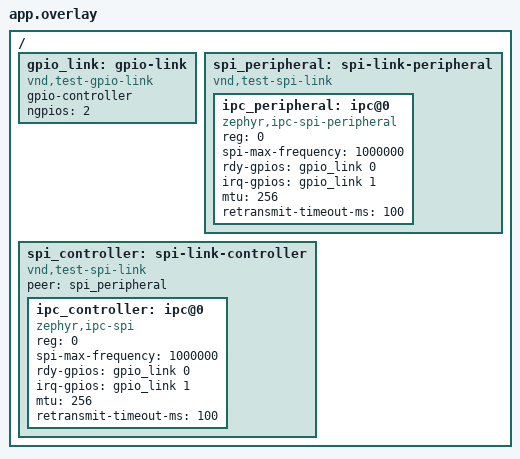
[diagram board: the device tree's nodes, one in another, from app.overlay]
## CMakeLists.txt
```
# SPDX-FileCopyrightText: Copyright (c) 2026 Basalte bv
# SPDX-License-Identifier: Apache-2.0

cmake_minimum_required(VERSION 3.28.0)
find_package(Zephyr REQUIRED HINTS $ENV{ZEPHYR_BASE})
project(ipc_link_spi)

target_sources(app PRIVATE src/main.c src/gpio_link.c src/spi_link.c)
```

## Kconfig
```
# SPDX-FileCopyrightText: Copyright (c) 2026 Basalte bv
# SPDX-License-Identifier: Apache-2.0

config TEST_IPC_LINK_SPI_MISMATCH
	bool "Test a peripheral with another frame size"
	help
	  Build the test of a controller facing a peripheral that runs
	  another frame size, with the mismatch overlay, instead of the
	  tests of a matching pair.

source "Kconfig.zephyr"
```

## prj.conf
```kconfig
CONFIG_ZTEST=y
CONFIG_IPC_SERVICE=y
CONFIG_IPC_SERVICE_LINK_STATS=y
CONFIG_GPIO=y
CONFIG_SPI=y
CONFIG_SPI_ASYNC=y
CONFIG_SPI_PERIPHERAL=y
```

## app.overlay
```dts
/*
 * SPDX-FileCopyrightText: Copyright (c) 2026 Basalte bv
 * SPDX-License-Identifier: Apache-2.0
 */

#include <zephyr/dt-bindings/gpio/gpio.h>

/ {
	gpio_link: gpio-link {
		compatible = "vnd,test-gpio-link";
		gpio-controller;
		#gpio-cells = <2>;
		ngpios = <2>;
	};

	spi_peripheral: spi-link-peripheral {
		compatible = "vnd,test-spi-link";
		#address-cells = <1>;
		#size-cells = <0>;

		ipc_peripheral: ipc@0 {
			compatible = "zephyr,ipc-spi-peripheral";
			reg = <0>;
			spi-max-frequency = <1000000>;
			rdy-gpios = <&gpio_link 0 GPIO_ACTIVE_HIGH>;
			irq-gpios = <&gpio_link 1 GPIO_ACTIVE_HIGH>;
			mtu = <256>;
			retransmit-timeout-ms = <100>;
		};
	};

	spi_controller: spi-link-controller {
		compatible = "vnd,test-spi-link";
		#address-cells = <1>;
		#size-cells = <0>;
		peer = <&spi_peripheral>;

		ipc_controller: ipc@0 {
			compatible = "zephyr,ipc-spi";
			reg = <0>;
			spi-max-frequency = <1000000>;
			rdy-gpios = <&gpio_link 0 GPIO_ACTIVE_HIGH>;
			irq-gpios = <&gpio_link 1 GPIO_ACTIVE_HIGH>;
			mtu = <256>;
			retransmit-timeout-ms = <100>;
		};
	};
};
```

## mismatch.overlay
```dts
/*
 * SPDX-FileCopyrightText: Copyright (c) 2026 Basalte bv
 * SPDX-License-Identifier: Apache-2.0
 */

/* The peripheral runs another frame size than the controller, and both probe slowly */
&ipc_peripheral {
	mtu = <128>;
	retransmit-timeout-ms = <1000>;
};

&ipc_controller {
	retransmit-timeout-ms = <1000>;
};
```

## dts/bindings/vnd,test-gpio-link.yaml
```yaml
# SPDX-FileCopyrightText: Copyright (c) 2026 Basalte bv
# SPDX-License-Identifier: Apache-2.0

description: |
  Test GPIO port whose pins are wires between two drivers in one image: a level written by one
  is read by the other, and fires its edge interrupts.

compatible: "vnd,test-gpio-link"

include: [gpio-controller.yaml, base.yaml]

properties:
  "#gpio-cells":
    const: 2

gpio-cells:
  - pin
  - flags
```

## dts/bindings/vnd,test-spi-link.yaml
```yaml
# SPDX-FileCopyrightText: Copyright (c) 2026 Basalte bv
# SPDX-License-Identifier: Apache-2.0

description: |
  Test SPI bus of a pair: a transfer on the controller bus runs against the transfer armed on
  its peer, the peripheral bus.

compatible: "vnd,test-spi-link"

include: spi-controller.yaml

properties:
  peer:
    type: phandle
    description: The peripheral bus, only set on the controller bus.
```

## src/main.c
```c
/*
 * SPDX-FileCopyrightText: Copyright (c) 2026 Basalte bv
 * SPDX-License-Identifier: Apache-2.0
 */

/*
 * A controller and a peripheral IPC link instance in one image, over a test SPI bus pair and a
 * test GPIO port, so both transfer threads, RDY and IRQ run as on two MCUs.
 */

#include <errno.h>
#include <string.h>

#include <zephyr/device.h>
#include <zephyr/drivers/gpio.h>
#include <zephyr/ipc/ipc_link.h>
#include <zephyr/ipc/ipc_service.h>
#include <zephyr/kernel.h>
#include <zephyr/sys/byteorder.h>
#include <zephyr/ztest.h>

#define BIND_TIMEOUT 1000
#define STREAM_COUNT 300
#define RETX_MS      DT_PROP(DT_NODELABEL(ipc_controller), retransmit_timeout_ms)
#define MAX_RETX     CONFIG_IPC_SERVICE_BACKEND_LINK_MAX_RETRANSMITS
/* Long enough for the retransmissions to end a session */
#define GONE_MS      (2 * (MAX_RETX + 1) * RETX_MS)

#define RDY_PIN DT_GPIO_PIN(DT_NODELABEL(ipc_controller), rdy_gpios)

static const struct device *const dev_c = DEVICE_DT_GET(DT_NODELABEL(ipc_controller));
static const struct device *const dev_p = DEVICE_DT_GET(DT_NODELABEL(ipc_peripheral));

extern atomic_t spi_link_transfers;

struct test_ept {
	struct ipc_ept ept;
	struct ipc_ept_cfg cfg;
	struct k_sem bound;
	struct k_sem unbound;
	struct k_sem received;
	uint8_t last[256];
	size_t last_len;
	uint32_t count;
	bool echo;
	bool stream;
	uint32_t expected;
	int error;
	/* Keep the received buffers */
	bool hold;
	const void *held[CONFIG_IPC_SERVICE_BACKEND_LINK_RX_BUFFERS];
	size_t held_count;
};

static void test_bound(void *priv)
{
	struct test_ept *t = priv;

	k_sem_give(&t->bound);
}

static void test_unbound(void *priv)
{
	struct test_ept *t = priv;

	k_sem_give(&t->unbound);
}

static void test_received(const void *data, size_t len, void *priv)
{
	struct test_ept *t = priv;

	t->count++;

	if (t->stream) {
		if (len != sizeof(uint32_t) || sys_get_le32(data) != t->expected) {
			t->error = -EBADMSG;
		}
		t->expected++;
	}

	if (len <= sizeof(t->last)) {
		memcpy(t->last, data, len);
		t->last_len = len;
	}

	if (t->echo) {
		int ret = ipc_service_send(&t->ept, data, len);

		if (ret < 0) {
			t->error = ret;
		}
	}

	if (t->hold && t->held_count < ARRAY_SIZE(t->held)) {
		if (ipc_service_hold_rx_buffer(&t->ept, (void *)data) == 0) {
			t->held[t->held_count++] = data;
		}
	}

	k_sem_give(&t->received);
}

static void test_ept_init(struct test_ept *t, const char *name)
{
	memset(t, 0, sizeof(*t));
	t->cfg.name = name;
	t->cfg.priv = t;
	t->cfg.cb.bound = test_bound;
	t->cfg.cb.unbound = test_unbound;
	t->cfg.cb.received = test_received;
	k_sem_init(&t->bound, 0, 1);
	k_sem_init(&t->unbound, 0, 1);
	k_sem_init(&t->received, 0, K_SEM_MAX_LIMIT);
}

static struct test_ept ept_c;

static uint32_t stat_get(const struct device *dev, size_t offset)
{
	struct ipc_link_stats stats;

	zassert_ok(ipc_link_stats_get(dev, &stats));

	return *(uint32_t *)((uint8_t *)&stats + offset);
}

#define STAT(dev, name) stat_get(dev, offsetof(struct ipc_link_stats, name))

static void *suite_setup(void)
{
	zassert_ok(ipc_service_open_instance(dev_p));
	zassert_ok(ipc_service_open_instance(dev_c));

	return NULL;
}

#ifdef CONFIG_TEST_IPC_LINK_SPI_MISMATCH

ZTEST_SUITE(ipc_link_spi_mismatch, NULL, suite_setup, NULL, NULL, NULL);

/* The peripheral runs another frame size: each side probes it once per timeout, no more */
ZTEST(ipc_link_spi_mismatch, test_probed_slowly)
{
	atomic_val_t transfers;

	k_sleep(K_MSEC(3 * RETX_MS));

	transfers = atomic_get(&spi_link_transfers);
	zassert_true(transfers >= 2 && transfers <= 8, "%ld transactions in %d ms", (long)transfers,
		     3 * RETX_MS);
	zexpect_true(STAT(dev_c, peer_mismatches) > 0);

	test_ept_init(&ept_c, "echo");
	zassert_ok(ipc_service_register_endpoint(dev_c, &ept_c.ept, &ept_c.cfg));
	zassert_equal(k_sem_take(&ept_c.bound, K_MSEC(RETX_MS)), -EAGAIN);
}

#else

static const struct device *const gpio = DEVICE_DT_GET(DT_NODELABEL(gpio_link));
static struct test_ept ept_p;
static struct test_ept ept_c2;

void spi_link_pulse(const struct device *dev);
void spi_link_unplug(bool unplugged);

/* Sends, waiting for room up to a timeout: the backend itself never waits */
static int send_wait(struct ipc_ept *ept, const void *data, size_t len, uint32_t timeout_ms)
{
	int64_t end = k_uptime_get() + timeout_ms;
	int ret;

	while (true) {
		ret = ipc_service_send(ept, data, len);
		if (ret != -ENOMEM || k_uptime_get() >= end) {
			return ret;
		}

		k_sleep(K_MSEC(1));
	}
}

static void register_pair(void)
{
	zassert_ok(ipc_service_register_endpoint(dev_p, &ept_p.ept, &ept_p.cfg));
	zassert_ok(ipc_service_register_endpoint(dev_c, &ept_c.ept, &ept_c.cfg));
	zassert_ok(k_sem_take(&ept_c.bound, K_MSEC(BIND_TIMEOUT)));
	zassert_ok(k_sem_take(&ept_p.bound, K_MSEC(BIND_TIMEOUT)));
}

static void before(void *fixture)
{
	ARG_UNUSED(fixture);

	test_ept_init(&ept_c, "echo");
	test_ept_init(&ept_p, "echo");
	test_ept_init(&ept_c2, "other");
}

static void after(void *fixture)
{
	struct test_ept *epts[] = {&ept_c, &ept_p, &ept_c2};

	ARG_UNUSED(fixture);

	spi_link_unplug(false);

	for (size_t i = 0; i < ARRAY_SIZE(epts); i++) {
		while (epts[i]->held_count > 0) {
			(void)ipc_service_release_rx_buffer(
				&epts[i]->ept, (void *)epts[i]->held[--epts[i]->held_count]);
		}

		(void)ipc_service_deregister_endpoint(&epts[i]->ept);
	}
}

ZTEST_SUITE(ipc_link_spi, NULL, suite_setup, before, after, NULL);

static void echo(struct test_ept *from, struct test_ept *to)
{
	to->echo = true;

	register_pair();

	zassert_equal(ipc_service_send(&from->ept, "hello", 5), 5);
	zassert_ok(k_sem_take(&from->received, K_MSEC(1000)));
	zassert_equal(from->last_len, 5);
	zassert_mem_equal(from->last, "hello", 5);
	zassert_equal(to->error, 0);
}

ZTEST(ipc_link_spi, test_echo_from_controller)
{
	echo(&ept_c, &ept_p);
}

/* The peripheral starts: its IRQ line makes the controller clock */
ZTEST(ipc_link_spi, test_echo_from_peripheral)
{
	echo(&ept_p, &ept_c);
}

ZTEST(ipc_link_spi, test_bind_later)
{
	/* The controller registers first, and binds once the peripheral registers */
	zassert_ok(ipc_service_register_endpoint(dev_c, &ept_c.ept, &ept_c.cfg));
	zassert_equal(k_sem_take(&ept_c.bound, K_MSEC(2 * RETX_MS)), -EAGAIN);

	zassert_ok(ipc_service_register_endpoint(dev_p, &ept_p.ept, &ept_p.cfg));
	zassert_ok(k_sem_take(&ept_c.bound, K_MSEC(BIND_TIMEOUT)));
	zassert_ok(k_sem_take(&ept_p.bound, K_MSEC(BIND_TIMEOUT)));
}

ZTEST(ipc_link_spi, test_largest_message)
{
	uint8_t big[256];
	int max;

	ept_p.echo = true;
	register_pair();

	max = ipc_service_get_tx_buffer_size(&ept_c.ept);
	zassert_true(max > 0 && max < sizeof(big));
	for (int i = 0; i < max; i++) {
		big[i] = (uint8_t)i;
	}

	zassert_equal(ipc_service_send(&ept_c.ept, big, max + 1), -EMSGSIZE);
	/* A frame of its own: wait for the bind traffic to be acknowledged */
	zassert_equal(send_wait(&ept_c.ept, big, max, 1000), max);
	zassert_ok(k_sem_take(&ept_c.received, K_MSEC(1000)));
	zexpect_equal(ept_c.last_len, max);
	zexpect_mem_equal(ept_c.last, big, max);
}

ZTEST(ipc_link_spi, test_stream_both_ways)
{
	ept_c.stream = true;
	ept_p.stream = true;

	register_pair();

	for (uint32_t i = 0; i < STREAM_COUNT; i++) {
		uint8_t data[sizeof(uint32_t)];
		int ret;

		sys_put_le32(i, data);

		ret = send_wait(&ept_c.ept, data, sizeof(data), 1000);
		zassert_equal(ret, sizeof(data), "message %u to the peripheral: %d", i, ret);

		ret = send_wait(&ept_p.ept, data, sizeof(data), 1000);
		zassert_equal(ret, sizeof(data), "message %u to the controller: %d", i, ret);
	}

	for (uint32_t i = 0; i < STREAM_COUNT; i++) {
		zassert_ok(k_sem_take(&ept_c.received, K_MSEC(1000)), "message %u", i);
		zassert_ok(k_sem_take(&ept_p.received, K_MSEC(1000)), "message %u", i);
	}

	zexpect_equal(ept_c.count, STREAM_COUNT);
	zexpect_equal(ept_p.count, STREAM_COUNT);
	zexpect_equal(ept_c.error, 0);
	zexpect_equal(ept_p.error, 0);
}

ZTEST(ipc_link_spi, test_hold)
{
	size_t count = 0;
	uint8_t big[256];
	int max;

	ept_p.hold = true;
	register_pair();

	/* The peripheral keeps every buffer: the controller runs out of credits, then out of
	 * room. Once they are released, the peripheral has credits to give and nothing else: it
	 * must ask for the transaction that carries them with IRQ
	 */
	max = ipc_service_get_tx_buffer_size(&ept_c.ept);

	while (true) {
		int ret = send_wait(&ept_c.ept, big, max, 3 * RETX_MS);

		if (ret == -ENOMEM) {
			break;
		}

		zassert_equal(ret, max);
		count++;
		zassert_true(count < 100, "the controller never ran out of room");
	}

	zexpect_equal(ept_p.held_count, CONFIG_IPC_SERVICE_BACKEND_LINK_RX_BUFFERS - 1);

	while (ept_p.held_count > 0) {
		zassert_ok(ipc_service_release_rx_buffer(&ept_p.ept,
							 (void *)ept_p.held[--ept_p.held_count]));
	}
	ept_p.hold = false;

	for (size_t i = 0; i < count; i++) {
		zassert_ok(k_sem_take(&ept_p.received, K_MSEC(1000)), "message %zu", i);
	}
	zexpect_equal(ept_p.count, count);
}

ZTEST(ipc_link_spi, test_unbind)
{
	ept_p.echo = true;
	register_pair();

	zassert_ok(ipc_service_deregister_endpoint(&ept_p.ept));
	zassert_ok(k_sem_take(&ept_c.unbound, K_MSEC(1000)));
	zassert_equal(ipc_service_send(&ept_c.ept, "x", 1), -EBUSY);

	zassert_ok(ipc_service_register_endpoint(dev_p, &ept_p.ept, &ept_p.cfg));
	zassert_ok(k_sem_take(&ept_c.bound, K_MSEC(BIND_TIMEOUT)));
	zassert_ok(k_sem_take(&ept_p.bound, K_MSEC(BIND_TIMEOUT)));

	zassert_equal(ipc_service_send(&ept_c.ept, "again", 5), 5);
	zassert_ok(k_sem_take(&ept_c.received, K_MSEC(1000)));
	zexpect_mem_equal(ept_c.last, "again", 5);
}

/* Waits until the controller clocks nothing for a while and the peripheral is armed */
static void wait_idle(void)
{
	atomic_val_t transfers;

	for (int i = 0; i < 100; i++) {
		transfers = atomic_get(&spi_link_transfers);
		k_sleep(K_MSEC(20));
		if (atomic_get(&spi_link_transfers) == transfers &&
		    gpio_pin_get(gpio, RDY_PIN) == 1) {
			return;
		}
	}

	zassert_unreachable("the link never went idle");
}

/* A chip select pulse without clocks delivers nothing: the stale receive buffer isn't a frame */
ZTEST(ipc_link_spi, test_peripheral_pulse)
{
	struct ipc_link_stats before;
	struct ipc_link_stats after;

	echo(&ept_c, &ept_p);
	wait_idle();

	zassert_ok(ipc_link_stats_get(dev_p, &before));
	spi_link_pulse(DEVICE_DT_GET(DT_NODELABEL(spi_peripheral)));

	for (int i = 0; i < 100; i++) {
		zassert_ok(ipc_link_stats_get(dev_p, &after));
		if (after.header_errors != before.header_errors) {
			break;
		}
		k_sleep(K_MSEC(1));
	}

	zassert_equal(after.header_errors, before.header_errors + 1);
	zassert_equal(after.rx_payloads, before.rx_payloads);
	zassert_equal(after.rx_dropped, before.rx_dropped);
	zassert_equal(ept_p.count, 1);

	zassert_equal(ipc_service_send(&ept_c.ept, "again", 5), 5);
	zassert_ok(k_sem_take(&ept_c.received, K_MSEC(1000)));
	zexpect_mem_equal(ept_c.last, "again", 5);
}

/*
 * The peripheral stops answering: no RDY, no transaction. The controller's timeouts end the
 * session all the same, and the link comes back once the peripheral does
 */
ZTEST(ipc_link_spi, test_peripheral_gone)
{
	uint32_t disconnects;
	int64_t start;

	ept_p.echo = true;
	register_pair();
	wait_idle();
	disconnects = STAT(dev_c, disconnects);

	/* Unplugged, with its RDY line dead */
	spi_link_unplug(true);
	zassert_ok(gpio_pin_set(gpio, RDY_PIN, 0));

	start = k_uptime_get();
	zassert_equal(ipc_service_send(&ept_c.ept, "anyone", 6), 6);
	zassert_ok(k_sem_take(&ept_c.unbound, K_MSEC(GONE_MS)));
	zassert_true(k_uptime_get() - start >= MAX_RETX * RETX_MS, "gone after %lld ms",
		     k_uptime_get() - start);
	zexpect_equal(STAT(dev_c, disconnects), disconnects + 1);

	/* Plugged back in, its armed transfer and RDY are as they were */
	spi_link_unplug(false);
	zassert_ok(gpio_pin_set(gpio, RDY_PIN, 1));

	zassert_ok(k_sem_take(&ept_p.unbound, K_MSEC(1000)));
	zassert_ok(k_sem_take(&ept_c.bound, K_MSEC(BIND_TIMEOUT)));
	zassert_ok(k_sem_take(&ept_p.bound, K_MSEC(BIND_TIMEOUT)));

	zassert_equal(ipc_service_send(&ept_c.ept, "back", 4), 4);
	zassert_ok(k_sem_take(&ept_c.received, K_MSEC(1000)));
	zexpect_mem_equal(ept_c.last, "back", 4);
}

/*
 * The peripheral stops answering while the controller only has a control message to send: the
 * bind of a new endpoint. It is timed like a payload, and ends the session
 */
ZTEST(ipc_link_spi, test_peripheral_gone_control)
{
	uint32_t disconnects;

	ept_p.echo = true;
	register_pair();
	wait_idle();
	disconnects = STAT(dev_c, disconnects);

	spi_link_unplug(true);
	zassert_ok(gpio_pin_set(gpio, RDY_PIN, 0));

	zassert_ok(ipc_service_register_endpoint(dev_c, &ept_c2.ept, &ept_c2.cfg));
	zassert_ok(k_sem_take(&ept_c.unbound, K_MSEC(GONE_MS)));
	zexpect_equal(STAT(dev_c, disconnects), disconnects + 1);

	spi_link_unplug(false);
	zassert_ok(gpio_pin_set(gpio, RDY_PIN, 1));

	zassert_ok(k_sem_take(&ept_p.unbound, K_MSEC(1000)));
	zassert_ok(k_sem_take(&ept_c.bound, K_MSEC(BIND_TIMEOUT)));
	zassert_ok(k_sem_take(&ept_p.bound, K_MSEC(BIND_TIMEOUT)));
}

#endif /* CONFIG_TEST_IPC_LINK_SPI_MISMATCH */
```

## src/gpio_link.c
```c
/*
 * SPDX-FileCopyrightText: Copyright (c) 2026 Basalte bv
 * SPDX-License-Identifier: Apache-2.0
 */

#define DT_DRV_COMPAT vnd_test_gpio_link

#include <zephyr/device.h>
#include <zephyr/drivers/gpio.h>
#include <zephyr/drivers/gpio/gpio_utils.h>
#include <zephyr/spinlock.h>

struct gpio_link_config {
	struct gpio_driver_config common;
};

struct gpio_link_data {
	struct gpio_driver_data common;
	struct k_spinlock lock;
	sys_slist_t callbacks;
	gpio_port_value_t values;
	gpio_port_pins_t rising;
	gpio_port_pins_t falling;
};

static void gpio_link_write(const struct device *dev, gpio_port_pins_t mask,
			    gpio_port_value_t values)
{
	struct gpio_link_data *data = dev->data;
	k_spinlock_key_t key = k_spin_lock(&data->lock);
	gpio_port_value_t old = data->values;
	gpio_port_pins_t fired;

	data->values = (old & ~mask) | (values & mask);
	fired = (data->values & ~old & data->rising) | (~data->values & old & data->falling);

	k_spin_unlock(&data->lock, key);

	if (fired != 0U) {
		gpio_fire_callbacks(&data->callbacks, dev, fired);
	}
}

static int gpio_link_pin_configure(const struct device *dev, gpio_pin_t pin, gpio_flags_t flags)
{
	if ((flags & GPIO_OUTPUT_INIT_HIGH) != 0U) {
		gpio_link_write(dev, BIT(pin), BIT(pin));
	} else if ((flags & GPIO_OUTPUT_INIT_LOW) != 0U) {
		gpio_link_write(dev, BIT(pin), 0U);
	} else {
		/* An input, or an output keeping its level */
	}

	return 0;
}

static int gpio_link_port_get_raw(const struct device *dev, gpio_port_value_t *values)
{
	struct gpio_link_data *data = dev->data;

	*values = data->values;

	return 0;
}

static int gpio_link_port_set_masked_raw(const struct device *dev, gpio_port_pins_t mask,
					 gpio_port_value_t values)
{
	gpio_link_write(dev, mask, values);

	return 0;
}

static int gpio_link_port_set_bits_raw(const struct device *dev, gpio_port_pins_t pins)
{
	gpio_link_write(dev, pins, pins);

	return 0;
}

static int gpio_link_port_clear_bits_raw(const struct device *dev, gpio_port_pins_t pins)
{
	gpio_link_write(dev, pins, 0U);

	return 0;
}

static int gpio_link_port_toggle_bits(const struct device *dev, gpio_port_pins_t pins)
{
	struct gpio_link_data *data = dev->data;

	gpio_link_write(dev, pins, ~data->values);

	return 0;
}

static int gpio_link_pin_interrupt_configure(const struct device *dev, gpio_pin_t pin,
					     enum gpio_int_mode mode, enum gpio_int_trig trig)
{
	struct gpio_link_data *data = dev->data;
	k_spinlock_key_t key;

	if (mode != GPIO_INT_MODE_DISABLED && mode != GPIO_INT_MODE_EDGE) {
		return -ENOTSUP;
	}

	key = k_spin_lock(&data->lock);

	data->rising &= ~BIT(pin);
	data->falling &= ~BIT(pin);

	if (mode == GPIO_INT_MODE_EDGE) {
		if (trig == GPIO_INT_TRIG_HIGH || trig == GPIO_INT_TRIG_BOTH) {
			data->rising |= BIT(pin);
		}

		if (trig == GPIO_INT_TRIG_LOW || trig == GPIO_INT_TRIG_BOTH) {
			data->falling |= BIT(pin);
		}
	}

	k_spin_unlock(&data->lock, key);

	return 0;
}

static int gpio_link_manage_callback(const struct device *dev, struct gpio_callback *callback,
				     bool set)
{
	struct gpio_link_data *data = dev->data;

	return gpio_manage_callback(&data->callbacks, callback, set);
}

static DEVICE_API(gpio, gpio_link_api) = {
	.pin_configure = gpio_link_pin_configure,
	.port_get_raw = gpio_link_port_get_raw,
	.port_set_masked_raw = gpio_link_port_set_masked_raw,
	.port_set_bits_raw = gpio_link_port_set_bits_raw,
	.port_clear_bits_raw = gpio_link_port_clear_bits_raw,
	.port_toggle_bits = gpio_link_port_toggle_bits,
	.pin_interrupt_configure = gpio_link_pin_interrupt_configure,
	.manage_callback = gpio_link_manage_callback,
};

#define GPIO_LINK_DEFINE(inst)                                                                     \
	static const struct gpio_link_config gpio_link_config_##inst = {                           \
		.common = GPIO_COMMON_CONFIG_FROM_DT_INST(inst),                                   \
	};                                                                                         \
                                                                                                   \
	static struct gpio_link_data gpio_link_data_##inst;                                        \
                                                                                                   \
	DEVICE_DT_INST_DEFINE(inst, NULL, NULL, &gpio_link_data_##inst, &gpio_link_config_##inst,  \
			      POST_KERNEL, CONFIG_GPIO_INIT_PRIORITY, &gpio_link_api);

DT_INST_FOREACH_STATUS_OKAY(GPIO_LINK_DEFINE)
```

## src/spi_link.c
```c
/*
 * SPDX-FileCopyrightText: Copyright (c) 2026 Basalte bv
 * SPDX-License-Identifier: Apache-2.0
 */

#define DT_DRV_COMPAT vnd_test_spi_link

#include <string.h>

#include <zephyr/device.h>
#include <zephyr/drivers/spi.h>
#include <zephyr/kernel.h>
#include <zephyr/spinlock.h>

/* Transactions run on the controller buses */
atomic_t spi_link_transfers;

/* The peripheral is unplugged: the controller clocks nothing and reads an idle bus */
static bool spi_link_unplugged;

struct spi_link_config {
	/* The peripheral bus, NULL on the peripheral bus itself */
	const struct device *peer;
};

struct spi_link_data {
	struct k_spinlock lock;
	/* The peripheral transfer, armed until a controller transfer runs it */
	bool armed;
	const struct spi_buf_set *tx;
	const struct spi_buf_set *rx;
	spi_callback_t cb;
	void *userdata;
};

static size_t spi_link_total(const struct spi_buf_set *set)
{
	size_t len = 0;

	for (size_t i = 0; set != NULL && i < set->count; i++) {
		len += set->buffers[i].len;
	}

	return len;
}

/* Byte at offset of a buffer set, 0 past its end or in a NULL buffer */
static uint8_t spi_link_get(const struct spi_buf_set *set, size_t offset)
{
	for (size_t i = 0; set != NULL && i < set->count; i++) {
		const struct spi_buf *buf = &set->buffers[i];

		if (offset < buf->len) {
			return buf->buf != NULL ? ((const uint8_t *)buf->buf)[offset] : 0U;
		}

		offset -= buf->len;
	}

	return 0U;
}

static void spi_link_put(const struct spi_buf_set *set, size_t offset, uint8_t val)
{
	for (size_t i = 0; set != NULL && i < set->count; i++) {
		const struct spi_buf *buf = &set->buffers[i];

		if (offset < buf->len) {
			if (buf->buf != NULL) {
				((uint8_t *)buf->buf)[offset] = val;
			}
			return;
		}

		offset -= buf->len;
	}
}

static int spi_link_transceive(const struct device *dev, const struct spi_config *config,
			       const struct spi_buf_set *tx_bufs, const struct spi_buf_set *rx_bufs)
{
	const struct spi_link_config *cfg = dev->config;
	struct spi_link_data *peer;
	struct spi_link_data armed;
	size_t len = MAX(spi_link_total(tx_bufs), spi_link_total(rx_bufs));
	k_spinlock_key_t key;

	if (SPI_OP_MODE_GET(config->operation) != SPI_OP_MODE_CONTROLLER || cfg->peer == NULL) {
		return -ENOTSUP;
	}

	peer = cfg->peer->data;
	atomic_inc(&spi_link_transfers);

	key = k_spin_lock(&peer->lock);
	armed = *peer;
	if (spi_link_unplugged) {
		armed.armed = false;
	} else {
		peer->armed = false;
	}
	k_spin_unlock(&peer->lock, key);

	/* An unarmed peripheral leaves its SDO idle high and receives nothing */
	for (size_t i = 0; i < len; i++) {
		spi_link_put(rx_bufs, i, armed.armed ? spi_link_get(armed.tx, i) : 0xffU);

		if (armed.armed) {
			spi_link_put(armed.rx, i, spi_link_get(tx_bufs, i));
		}
	}

	if (armed.armed) {
		armed.cb(cfg->peer, (int)MIN(len, spi_link_total(armed.rx)), armed.userdata);
		/* The peripheral processes the transfer on its own processor: let its thread run
		 * before the controller goes on
		 */
		k_yield();
	}

	return 0;
}

static int spi_link_transceive_async(const struct device *dev, const struct spi_config *config,
				     const struct spi_buf_set *tx_bufs,
				     const struct spi_buf_set *rx_bufs, spi_callback_t cb,
				     void *userdata)
{
	struct spi_link_data *data = dev->data;
	k_spinlock_key_t key;

	if (SPI_OP_MODE_GET(config->operation) != SPI_OP_MODE_PERIPHERAL) {
		return -ENOTSUP;
	}

	key = k_spin_lock(&data->lock);

	if (data->armed) {
		k_spin_unlock(&data->lock, key);
		return -EBUSY;
	}

	data->tx = tx_bufs;
	data->rx = rx_bufs;
	data->cb = cb;
	data->userdata = userdata;
	data->armed = true;

	k_spin_unlock(&data->lock, key);

	return 0;
}

/* On the peripheral bus, completes the armed transfer without moving a byte */
static void spi_link_complete(const struct device *dev, int result)
{
	struct spi_link_data *data = dev->data;
	struct spi_link_data armed;
	k_spinlock_key_t key;

	key = k_spin_lock(&data->lock);
	armed = *data;
	data->armed = false;
	k_spin_unlock(&data->lock, key);

	if (armed.armed) {
		armed.cb(dev, result, armed.userdata);
	}
}

/* A chip select pulse without clocks: the peripheral driver reports nothing received */
void spi_link_pulse(const struct device *dev)
{
	spi_link_complete(dev, 0);
}

/* Unplugs the peripheral from the controller, or plugs it back in */
void spi_link_unplug(bool unplugged)
{
	spi_link_unplugged = unplugged;
}

/* On the peripheral bus, cancels the armed transfer */
static int spi_link_release(const struct device *dev, const struct spi_config *config)
{
	ARG_UNUSED(config);

	spi_link_complete(dev, -ECANCELED);

	return 0;
}

static DEVICE_API(spi, spi_link_api) = {
	.transceive = spi_link_transceive,
	.transceive_async = spi_link_transceive_async,
	.release = spi_link_release,
};

/* The peripheral bus a controller bus is wired to */
#define SPI_LINK_PEER(inst)                                                                        \
	COND_CODE_1(DT_INST_NODE_HAS_PROP(inst, peer),                                             \
		    (DEVICE_DT_GET(DT_INST_PHANDLE(inst, peer))), (NULL))

#define SPI_LINK_DEFINE(inst)                                                                      \
	static const struct spi_link_config spi_link_config_##inst = {                             \
		.peer = SPI_LINK_PEER(inst),                                                       \
	};                                                                                         \
                                                                                                   \
	static struct spi_link_data spi_link_data_##inst;                                          \
                                                                                                   \
	DEVICE_DT_INST_DEFINE(inst, NULL, NULL, &spi_link_data_##inst, &spi_link_config_##inst,    \
			      POST_KERNEL, CONFIG_SPI_INIT_PRIORITY, &spi_link_api);

DT_INST_FOREACH_STATUS_OKAY(SPI_LINK_DEFINE)
```
